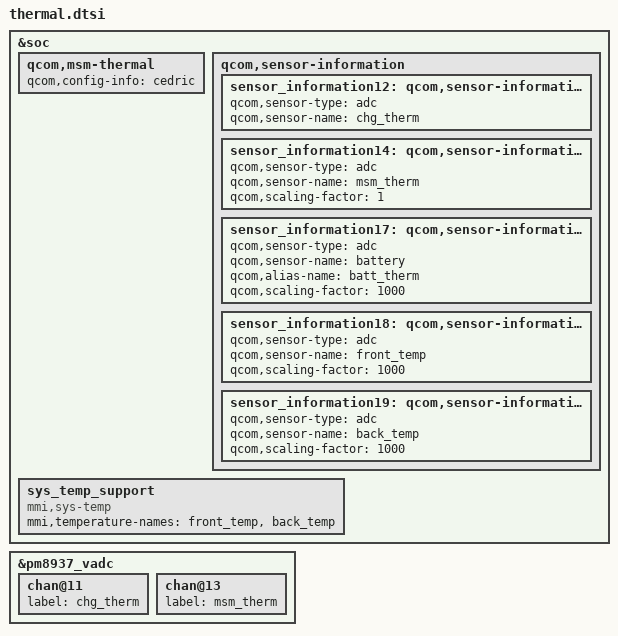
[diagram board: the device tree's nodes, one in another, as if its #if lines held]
&soc {
	qcom,msm-thermal {
		qcom,config-info = "cedric";
	};

	qcom,sensor-information {
		sensor_information12: qcom,sensor-information-12 {
			qcom,sensor-type = "adc";
			qcom,sensor-name = "chg_therm";
		};

#ifdef IS_MSM8917
		sensor_information14: qcom,sensor-information-14 {
			qcom,sensor-type = "adc";
			qcom,sensor-name = "msm_therm";
			qcom,scaling-factor = <1>;
		};
#else
		sensor_information15: qcom,sensor-information-15 {
			qcom,sensor-type = "adc";
			qcom,sensor-name = "msm_therm";
		};
#endif

		sensor_information17: qcom,sensor-information-17 {
			qcom,sensor-type = "adc";
			qcom,sensor-name = "battery";
			qcom,alias-name  = "batt_therm";
			qcom,scaling-factor = <1000>;
		};

		sensor_information18: qcom,sensor-information-18 {
			qcom,sensor-type = "adc";
			qcom,sensor-name = "front_temp";
			qcom,scaling-factor = <1000>;
		};

		sensor_information19: qcom,sensor-information-19 {
			qcom,sensor-type = "adc";
			qcom,sensor-name = "back_temp";
			qcom,scaling-factor = <1000>;
		};
	};

	sys_temp_support {
		compatible = "mmi,sys-temp";
		mmi,temperature-names = "front_temp",
					"back_temp";
		status = "ok";
	};
};

&pm8937_vadc {
	chan@11 {
		label = "chg_therm";
	};

	chan@13 {
		label = "msm_therm";
	};
};
